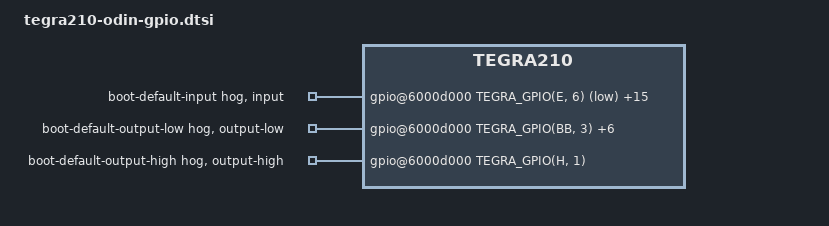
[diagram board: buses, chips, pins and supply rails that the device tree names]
/*
 * Copyright (c) 2019-2020, Billy Laws <blaws05@gmail.com>
 * Copyright (c) 2018-2023, CTCaer <ctcaer@gmail.com>
 *
 * This program is free software; you can redistribute it and/or modify
 * it under the terms of the GNU General Public License as published by
 * the Free Software Foundation; version 2 of the License.
 *
 * This program is distributed in the hope that it will be useful, but WITHOUT
 * ANY WARRANTY; without even the implied warranty of MERCHANTABILITY or
 * FITNESS FOR A PARTICULAR PURPOSE.  See the GNU General Public License for
 * more details.
 *
 */

#include <dt-bindings/gpio/tegra-gpio.h>

/ {
	gpio@6000d000 {
		boot-default-input {
			gpio-hog;
			input;
			gpios = <
				TEGRA_GPIO(E, 6) 1 /* Joycon (L) Wake Detect */
				TEGRA_GPIO(H, 6) 1 /* Joycon (R) Wake Detect */
				TEGRA_GPIO(X, 5) 0 /* Power Button (Not connected) */
				TEGRA_GPIO(Y, 1) 1 /* Home Button (RCM) */
				TEGRA_GPIO(S, 1) 1 /* Charger IC (BQ24193) Battery Charge Status */
				TEGRA_GPIO(S, 3) 1 /* Gamecard Detect */
				TEGRA_GPIO(Z, 3) 1 /* SD Card Write Protected */
				TEGRA_GPIO(H, 2) 1 /* Wi-Fi Wake Host */
				TEGRA_GPIO(H, 5) 1 /* Bluetooth - BT Module -> Wake AP */
				TEGRA_GPIO(K, 0) 0 /* Bluetooth Gpio2 */
				TEGRA_GPIO(K, 1) 0 /* Bluetooth Gpio3 */
				TEGRA_GPIO(K, 2) 0 /* Bluetooth Gpio4 */
				TEGRA_GPIO(V, 3) 1 /* Unused */

				TEGRA_GPIO(P, 0) 1  /* SDEV Odin/Modin */
				TEGRA_GPIO(BB, 2) 0 /* Ram Code 3 */
				TEGRA_GPIO(CC, 2) 0 /* Ram Code 2 */
				>;
			line-name = "boot-default-input";
		};

		boot-default-output-low {
			gpio-hog;
			output-low;
			gpios = <
				TEGRA_GPIO(BB, 3) 0 /* Gamecard Reset */
				TEGRA_GPIO(V, 5) 0  /* USB-PD (BM92T36) Reset. Use it to reset bm92t? */
				TEGRA_GPIO(K, 5) 0  /* USB-PD (BM92T36) VCONN Power Enable. HOS sets it to 0 */
				TEGRA_GPIO(J, 5) 0  /* Charger IC (BQ24193) Charge Select 1 */
				TEGRA_GPIO(L, 0) 0  /* Charger IC (BQ24193) Charge Select 2 */
				TEGRA_GPIO(H, 0) 0  /* Wi-Fi RF Disable */
				TEGRA_GPIO(H, 7) 0  /* TODO: What's this? Bluetooth Gpio5 */
				>;
			line-name = "boot-default-output-low";
		};

		boot-default-output-high {
			gpio-hog;
			output-high;
			gpios = <
				TEGRA_GPIO(H, 1) 0  /* Wi-Fi Reset. Powered on by default. */
				>;
			line-name = "boot-default-output-high";
		};

		system-suspend-output-low {
			gpio-suspend;
			suspend-output-low;
			output-low;
			gpios = <
				TEGRA_GPIO(V, 0) 0  /* LCD Backlight PWM */
				TEGRA_GPIO(V, 1) 0  /* LCD Backlight Enable */
				TEGRA_GPIO(V, 2) 0  /* LCD Reset */
				TEGRA_GPIO(H, 1) 0  /* Wi-Fi Reset. Powered off in suspend. */
				TEGRA_GPIO(CC, 3) 0 /* Joycon (L) Charge Enable */
				TEGRA_GPIO(K, 3) 0  /* Joycon (R) Charge Enable */
				>;
		};
	};
};
